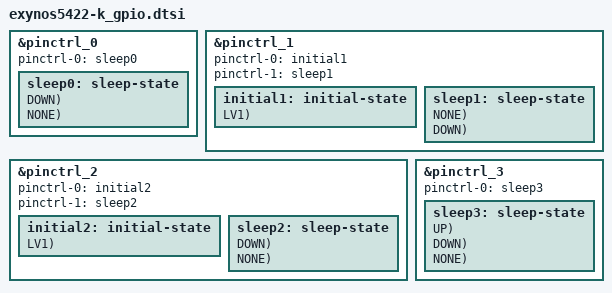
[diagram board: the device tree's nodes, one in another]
/*
 * SAMSUNG UNIVERSAL5430 board device tree source
 *
 * Copyright (c) 2014 Samsung Electronics Co., Ltd.
 *		http://www.samsung.com
 *
 * This program is free software; you can redistribute it and/or modify
 * it under the terms of the GNU General Public License version 2 as
 * published by the Free Software Foundation.
*/

#include "exynos_gpio_config_macros.dtsi"

&pinctrl_0 {
	pinctrl-names = "sleep";

	pinctrl-0 = <&sleep0>;

sleep0: sleep-state {
		PIN_SLP(gpy7-2, INPUT, DOWN);	/* NC */
		PIN_SLP(gpy7-3, INPUT, DOWN);	/* CAM_SENSOR_DET */
		PIN_SLP(gpy7-4, PREV, NONE);	/* MLCD_RST */
	};
};

&pinctrl_1 {
	pinctrl-names = "default", "sleep";

	pinctrl-0 = <&initial1>;
	pinctrl-1 = <&sleep1>;

initial1: initial-state {
		  PIN_IN(gpc2-2, DOWN, LV1);	/* NC */
		  PIN_IN(gpy0-0, DOWN, LV1);	/* NC */
		  PIN_IN(gpy0-1, DOWN, LV1);	/* NC */
		  PIN_IN(gpy0-2, DOWN, LV1);	/* NC */
		  PIN_IN(gpy0-3, DOWN, LV1);	/* NC */
		  PIN_IN(gpy0-4, DOWN, LV1);	/* NC */
		  PIN_IN(gpy0-5, DOWN, LV1);	/* NC */

		  PIN_IN(gpy1-0, DOWN, LV1);	/* NC */
		  PIN_IN(gpy1-1, DOWN, LV1);	/* NC */
		  PIN_IN(gpy1-2, DOWN, LV1);	/* NC */
		  PIN_IN(gpy1-3, DOWN, LV1);	/* NC */

		  PIN_IN(gpy2-1, DOWN, LV1);	/* NC */
		  PIN_IN(gpy2-2, DOWN, LV1);	/* NC */

		  PIN_IN(gpy2-3, DOWN, LV1);	/* NC */
		  PIN_IN(gpy2-4, DOWN, LV1);	/* NC */
		  PIN_IN(gpy2-5, DOWN, LV1);	/* NC */

		  PIN_IN(gpy3-6, NONE, LV1);	/* SVC_I2C_SDA */
		  PIN_IN(gpy3-7, NONE, LV1);	/* SVC_I2C_SCL */

		  PIN_IN(gpy4-2, DOWN, LV1);	/* NC */
		  PIN_IN(gpy4-3, DOWN, LV1);	/* NC */
	  };

sleep1: sleep-state {
		PIN_SLP(gpc0-0, PREV, NONE);	/* NAND_CLK */
		PIN_SLP(gpc0-1, PREV, NONE);	/* NAND_CMD */
		PIN_SLP(gpc0-2, PREV, NONE);	/* eMMC_EN */
		PIN_SLP(gpc0-3, PREV, NONE);	/* NAND_D(0) */
		PIN_SLP(gpc0-4, PREV, NONE);	/* NAND_D(1) */
		PIN_SLP(gpc0-5, PREV, NONE);	/* NAND_D(2) */
		PIN_SLP(gpc0-6, PREV, NONE);	/* NAND_D(3) */
		PIN_SLP(gpc0-7, PREV, NONE);	/* EMMC_RCLK */

		PIN_SLP(gpc1-0, OUT0, NONE);	/* WLAN_SDIO_CLK */
		PIN_SLP(gpc1-1, INPUT, NONE);	/* WLAN_SDIO_CMD */
		PIN_SLP(gpc1-2, INPUT, DOWN);	/* NC */
		PIN_SLP(gpc1-3, INPUT, NONE);	/* WLAN_SDIO_D(0) */
		PIN_SLP(gpc1-4, INPUT, NONE);	/* WLAN_SDIO_D(1) */
		PIN_SLP(gpc1-5, INPUT, NONE);	/* WLAN_SDIO_D(2) */
		PIN_SLP(gpc1-6, INPUT, NONE);	/* WLAN_SDIO_D(3) */
		PIN_SLP(gpc1-7, INPUT, DOWN);	/* NC */

		PIN_SLP(gpc2-0, INPUT, DOWN);	/* T_FLASH_CLK */
		PIN_SLP(gpc2-1, INPUT, DOWN);	/* T_FLASH_CMD */
		PIN_SLP(gpc2-2, INPUT, DOWN);	/* NC */
		PIN_SLP(gpc2-3, INPUT, DOWN);	/* T_FLASH_D(0) */
		PIN_SLP(gpc2-4, INPUT, DOWN);	/* T_FLASH_D(1) */
		PIN_SLP(gpc2-5, INPUT, DOWN);	/* T_FLASH_D(2) */
		PIN_SLP(gpc2-6, INPUT, DOWN);	/* T_FLASH_D(3) */

		PIN_SLP(gpc3-0, PREV, NONE);	/* NAND_D(4) */
		PIN_SLP(gpc3-1, PREV, NONE);	/* NAND_D(5) */
		PIN_SLP(gpc3-2, PREV, NONE);	/* NAND_D(6) */
		PIN_SLP(gpc3-3, PREV, NONE);	/* NAND_D(7) */

		PIN_SLP(gpc4-0, INPUT, DOWN);	/* NC */
		PIN_SLP(gpc4-1, INPUT, DOWN);	/* NC */

		PIN_SLP(gpd1-0, OUT0, DOWN);	/* COMPANION_RSTN */
		PIN_SLP(gpd1-1, OUT0, NONE);	/* BTP_SLEEP/RST_N */
		PIN_SLP(gpd1-2, OUT0, DOWN);	/* VT_CAM_1.2V_EN */
		PIN_SLP(gpd1-3, INPUT, DOWN);	/* OCTA_ID */
		PIN_SLP(gpd1-4, INPUT, DOWN);	/* TOUCH_I2C_SDA */
		PIN_SLP(gpd1-5, INPUT, DOWN);	/* TOUCH_I2C_SCL */
		PIN_SLP(gpd1-6, OUT0, DOWN);	/* MAIN_CAM_A2.8V_EN */
		PIN_SLP(gpd1-7, INPUT, DOWN);	/* LCD_TE */

		PIN_SLP(gpy0-0, INPUT, DOWN);	/* NC */
		PIN_SLP(gpy0-1, INPUT, DOWN);	/* NC */
		PIN_SLP(gpy0-2, INPUT, DOWN);	/* NC */
		PIN_SLP(gpy0-3, INPUT, DOWN);	/* NC */
		PIN_SLP(gpy0-4, INPUT, DOWN);	/* NC */
		PIN_SLP(gpy0-5, INPUT, DOWN);	/* NC */

		PIN_SLP(gpy1-0, INPUT, DOWN);	/* NC */
		PIN_SLP(gpy1-1, INPUT, DOWN);	/* NC */
		PIN_SLP(gpy1-2, INPUT, DOWN);	/* NC */
		PIN_SLP(gpy1-3, INPUT, DOWN);	/* NC */

		PIN_SLP(gpy2-0, PREV, NONE);	/* TF_EN */
		PIN_SLP(gpy2-1, INPUT, DOWN);	/* NC */
		PIN_SLP(gpy2-2, INPUT, DOWN);	/* NC */
		PIN_SLP(gpy2-3, INPUT, DOWN);	/* NC */
		PIN_SLP(gpy2-4, INPUT, DOWN);	/* NC */
		PIN_SLP(gpy2-5, INPUT, DOWN);	/* NC */

		PIN_SLP(gpy3-0, PREV, NONE);	/* MMC01_EN */
		PIN_SLP(gpy3-1, PREV, NONE);	/* MMC2_EN */
		PIN_SLP(gpy3-2, OUT0, NONE);	/* MIPI_1.8V_EN */
		PIN_SLP(gpy3-3, PREV, NONE);	/* CODEC_POWER_EN */
		PIN_SLP(gpy3-4, INPUT, NONE);	/* SIM_SLOT */
		PIN_SLP(gpy3-5, PREV, NONE);	/* TSP_EN */
		PIN_SLP(gpy3-6, INPUT, NONE);	/* SVC_I2C_SDA */
		PIN_SLP(gpy3-7, INPUT, NONE);	/* SVC_I2C_SCL */

		PIN_SLP(gpy4-0, PREV, NONE);	/* BTP_LDO_EN */
		PIN_SLP(gpy4-1, INPUT, DOWN);	/* NC */
		PIN_SLP(gpy4-2, INPUT, DOWN);	/* NC */
		PIN_SLP(gpy4-3, INPUT, DOWN);	/* NC */
		PIN_SLP(gpy4-4, INPUT, DOWN);	/* NC */
		PIN_SLP(gpy4-5, INPUT, DOWN);	/* NC */
		PIN_SLP(gpy4-6, INPUT, DOWN);	/* NC */
		PIN_SLP(gpy4-7, INPUT, DOWN);	/* NC */

		PIN_SLP(gpy5-0, INPUT, DOWN);	/* NC */
		PIN_SLP(gpy5-1, INPUT, DOWN);	/* NC */
		PIN_SLP(gpy5-2, INPUT, DOWN);	/* NC */
		PIN_SLP(gpy5-3, INPUT, DOWN);	/* NC */
		PIN_SLP(gpy5-4, INPUT, DOWN);	/* NC */
		PIN_SLP(gpy5-5, INPUT, DOWN);	/* NC */
		PIN_SLP(gpy5-6, INPUT, DOWN);	/* NC */
		PIN_SLP(gpy5-7, INPUT, DOWN);	/* NC */

		PIN_SLP(gpy6-0, INPUT, DOWN);	/* NC */
		PIN_SLP(gpy6-1, INPUT, DOWN);	/* NC */
		PIN_SLP(gpy6-2, INPUT, DOWN);	/* NC */
		PIN_SLP(gpy6-3, INPUT, DOWN);	/* NC */
		PIN_SLP(gpy6-4, INPUT, DOWN);	/* NC */
		PIN_SLP(gpy6-5, INPUT, DOWN);	/* NC */
		PIN_SLP(gpy6-6, INPUT, DOWN);	/* NC */
		PIN_SLP(gpy6-7, INPUT, DOWN);	/* NC */
	};
};

&pinctrl_2 {
	pinctrl-names = "default", "sleep";

	pinctrl-0 = <&initial2>;
	pinctrl-1 = <&sleep2>;

initial2: initial-state {
		  PIN_IN(gpe0-7, DOWN, LV1);	/* NC */
		  PIN_IN(gpe1-1, DOWN, LV1);	/* NC */
		  PIN_IN(gpf1-4, DOWN, LV1);	/* NC */
		  PIN_IN(gpf1-5, DOWN, LV1);	/* NC */
		  PIN_IN(gpf1-6, DOWN, LV1);	/* NC */
		  PIN_IN(gpf1-7, DOWN, LV1);	/* NC */
	  };

sleep2: sleep-state {
		PIN_SLP(gpe0-0, OUT0, DOWN);	/* VT_CAM_STBY */
		PIN_SLP(gpe0-1, PREV, NONE);	/* FLASH_LED_EN */
		PIN_SLP(gpe0-2, PREV, NONE);	/* FLASH_LED_SET */
		PIN_SLP(gpe0-3, OUT0, DOWN);	/* VT_CAM_NRST */
		PIN_SLP(gpe0-4, OUT0, DOWN);	/* MAIN_CAM_RST */
		PIN_SLP(gpe0-5, OUT0, DOWN);	/* COMP_EN */
		PIN_SLP(gpe0-6, OUT0, DOWN);	/* MAIN_CAM_SPI_CSN_GP */
		PIN_SLP(gpe0-7, INPUT, DOWN);	/* NC */

		PIN_SLP(gpe1-0, INPUT, DOWN);	/* COMP_SPI_INT */
		PIN_SLP(gpe1-1, INPUT, DOWN);	/* NC */

		PIN_SLP(gpf0-0, INPUT, DOWN);	/* MAIN_CAM_SDA */
		PIN_SLP(gpf0-1, INPUT, DOWN);	/* MAIN_CAM_SCL */
		PIN_SLP(gpf0-2, INPUT, DOWN);	/* AF_SDA */
		PIN_SLP(gpf0-3, INPUT, DOWN);	/* AF_SCL */
		PIN_SLP(gpf0-4, INPUT, DOWN);	/* VT_CAM_SDA */
		PIN_SLP(gpf0-5, INPUT, DOWN);	/* VT_CAM_SCL */

		PIN_SLP(gpf1-0, OUT0, DOWN);	/* MAIN_CAM_SPI_SCLK */
		PIN_SLP(gpf1-1, OUT0, DOWN);	/* MAIN_CAM_SPI_SSN */
		PIN_SLP(gpf1-2, OUT0, DOWN);	/* MAIN_CAM_SPI_MISO */
		PIN_SLP(gpf1-3, OUT0, DOWN);	/* MAIN_CAM_SPI_MOSI */
		PIN_SLP(gpf1-4, INPUT, DOWN);	/* NC */
		PIN_SLP(gpf1-5, INPUT, DOWN);	/* NC */
		PIN_SLP(gpf1-6, INPUT, DOWN);	/* NC */
		PIN_SLP(gpf1-7, INPUT, DOWN);	/* NC */

		PIN_SLP(gpg0-0, OUT1, NONE);	/* MCU_nRST_1.8V */
		PIN_SLP(gpg0-1, PREV, NONE);	/* CODEC_LDO_EN */
		PIN_SLP(gpg0-2, PREV, NONE);	/* CDONE */
		PIN_SLP(gpg0-3, INPUT, DOWN);	/* MHL_INT */
		PIN_SLP(gpg0-4, INPUT, DOWN);	/* COMP_BUCK_I2C_SCL */
		PIN_SLP(gpg0-5, INPUT, DOWN);	/* COMP_BUCK_I2C_SDA */
		PIN_SLP(gpg0-6, INPUT, DOWN);	/* PCD_INT */
		PIN_SLP(gpg0-7, PREV, DOWN);	/* BT_EN */

		PIN_SLP(gpg1-0, PREV, NONE);	/* IPC_SLAVE_WAKEUP */
		PIN_SLP(gpg1-1, PREV, DOWN);	/* NFC_FIRMWARE */
		PIN_SLP(gpg1-2, PREV, NONE);	/* NFC_EN */
		PIN_SLP(gpg1-3, OUT0, NONE);	/* SUSPEND_REQUEST_HSIC */
		PIN_SLP(gpg1-4, PREV, NONE);	/* CP_ON */
		PIN_SLP(gpg1-5, INPUT, DOWN);	/* TSP_ID */
		PIN_SLP(gpg1-6, PREV, NONE);	/* AP_DUMP_INT */
		PIN_SLP(gpg1-7, INPUT, DOWN);	/* ACTIVE_STATE_HSIC */

		PIN_SLP(gpg2-0, PREV, NONE);	/* CODEC_RESET_N */
		PIN_SLP(gpg2-1, PREV, NONE);	/* CORE_MODE */

		PIN_SLP(gpj4-0, INPUT, DOWN);	/* LCD_TE */
		PIN_SLP(gpj4-1, OUT1, NONE);	/* RESET_REQ_N */
		PIN_SLP(gpj4-2, OUT1, NONE);	/* CRESET_B */
		PIN_SLP(gpj4-3, OUT1, NONE);	/* MHL_RST */
	};
};

&pinctrl_3 {
	pinctrl-names = "sleep";
	pinctrl-0 = <&sleep3>;
sleep3: sleep-state {
		PIN_SLP(gpa0-0, INPUT, UP);	/* BT_UART_RXD */
		PIN_SLP(gpa0-1, OUT1, UP);	/* BT_UART_TXD */
		PIN_SLP(gpa0-2, INPUT, UP);	/* BT_UART_CTS */
		PIN_SLP(gpa0-3, OUT1, UP);	/* BT_UART_RTS */
		PIN_SLP(gpa0-4, INPUT, UP);	/* GPS_UART_RXD */
		PIN_SLP(gpa0-5, INPUT, UP);	/* GPS_UART_TXD */
		PIN_SLP(gpa0-6, INPUT, DOWN);	/* GPS_UART_CTS */
		PIN_SLP(gpa0-7, OUT1, NONE);	/* GPS_UART_RTS */

		PIN_SLP(gpa1-0, INPUT, DOWN);	/* AP_RXD */
		PIN_SLP(gpa1-1, INPUT, DOWN);	/* AP_TXD */
		PIN_SLP(gpa1-2, INPUT, NONE);	/* NFC_SDA_1.8V */
		PIN_SLP(gpa1-3, INPUT, NONE);	/* NFC_SCL_1.8V */
		PIN_SLP(gpa1-4, INPUT, DOWN);	/* HEALTH_UART_RXD */
		PIN_SLP(gpa1-5, INPUT, DOWN);	/* HEALTH_UART_TXD */

		PIN_SLP(gpa2-0, OUT0, NONE);	/* SHUB_SPI_SCK */
		PIN_SLP(gpa2-1, OUT0, NONE);	/* SHUB_SPI_SSN */
		PIN_SLP(gpa2-2, INPUT, DOWN);	/* SHUB_SPI_MISO */
		PIN_SLP(gpa2-3, OUT0, NONE);	/* SHUB_SPI_MOSI */
		PIN_SLP(gpa2-4, OUT0, NONE);	/* BTP_SPI_CLK */
		PIN_SLP(gpa2-5, OUT0, NONE);	/* BTP_SPI_CS_N */
		PIN_SLP(gpa2-6, INPUT, DOWN);	/* BTP_SPI_MISO */
		PIN_SLP(gpa2-7, OUT0, NONE);	/* BTP_SPI_MOSI */

		PIN_SLP(gpb0-0, PREV, NONE);	/* LCD_1P5_EN */
		PIN_SLP(gpb0-1, INPUT, DOWN);	/* ERR_FG */
		PIN_SLP(gpb0-2, OUT0, DOWN);	/* HEALTH_EN */
		PIN_SLP(gpb0-3, INPUT, NONE);	/* FUEL_SDA_1.8V */
		PIN_SLP(gpb0-4, INPUT, NONE);	/* FUEL_SCL_1.8V */

		PIN_SLP(gpb1-0, INPUT, NONE);	/* FPGA_SPI_SI */
		PIN_SLP(gpb1-1, OUT0, NONE);	/* CODEC_SPI_SCK */
		PIN_SLP(gpb1-2, OUT0, NONE);	/* CODEC_SPI_SSN */
		PIN_SLP(gpb1-3, INPUT, DOWN);	/* CODEC_SPI_MISO */
		PIN_SLP(gpb1-4, OUT0, NONE);	/* CODEC_SPI_MOSI */

		PIN_SLP(gpb2-0, OUT0, NONE);	/* VIBTONE_PWM */
		PIN_SLP(gpb2-1, INPUT, NONE);	/* COVER_ID */
		PIN_SLP(gpb2-2, INPUT, NONE);	/* AP_PMIC_SDA */
		PIN_SLP(gpb2-3, INPUT, NONE);	/* AP_PMIC_SCL */

		PIN_SLP(gpb3-2, INPUT, DOWN);	/* VT_CAM_SDA */
		PIN_SLP(gpb3-3, INPUT, DOWN);	/* VT_CAM_SCL */
		PIN_SLP(gpb3-4, INPUT, NONE);	/* MEM_LDO_SCL */
		PIN_SLP(gpb3-5, INPUT, NONE);	/* MEM_LDO_SDA */
		PIN_SLP(gpb3-6, INPUT, NONE);	/* IF_PMIC_SDA */
		PIN_SLP(gpb3-7, INPUT, NONE);	/* IF_PMIC_SCL */

		PIN_SLP(gpb4-0, INPUT, DOWN);	/* MHL_SDA_1.8V */
		PIN_SLP(gpb4-1, INPUT, DOWN);	/* MHL_SCL_1.8V */

		PIN_SLP(gph0-0, INPUT, NONE);	/* HW_REV0 */
		PIN_SLP(gph0-1, INPUT, NONE);	/* HW_REV1 */
		PIN_SLP(gph0-2, INPUT, NONE);	/* HW_REV2 */
		PIN_SLP(gph0-3, INPUT, NONE);	/* HW_REV3 */
		PIN_SLP(gph0-4, INPUT, NONE);	/* FPGA_SPI_CLK */
		PIN_SLP(gph0-5, OUT0, DOWN);	/* MAIN_CAM_MCLK */
		PIN_SLP(gph0-6, OUT0, NONE);	/* 24MHZ_CLK_OUTPUT */
		PIN_SLP(gph0-7, OUT0, DOWN);	/* VT_CAM_MCLK */
	};
};
